VERSION ""

NS_ :

BS_:

BU_: BMS

BO_ 1568 Bat12V: 8 BMS
 SG_ Bat12V_voltage : 15|8@0+ (0.1,0) [0|1] ""  BMS

BO_ 2028 UDS_response: 8 BMS
 SG_ Frame_type M : 7|4@0+ (1,0) [0|1] ""  BMS
 SG_ bytes : 3|4@0+ (1,0) [0|1] ""  BMS
 SG_ Service_ID m0 : 15|8@0+ (1,0) [0|1] ""  BMS
 SG_ Data4 : 39|8@0+ (1,0) [0|1] ""  BMS
 SG_ Data5 : 47|8@0+ (1,0) [0|1] ""  BMS
 SG_ Data6 : 55|8@0+ (1,0) [0|1] ""  BMS
 SG_ Data7 : 63|8@0+ (1,0) [0|1] ""  BMS
 SG_ ReadDataByIdentifie m34 : 23|8@0+ (1,0) [0|1] ""  BMS

BO_ 2147484963 BCM: 8 BMS
 SG_ Ign : 7|4@0+ (1,0) [0|1] ""  BMS
 SG_ AliveCounter : 56|2@1+ (1,0) [0|3] ""  BMS

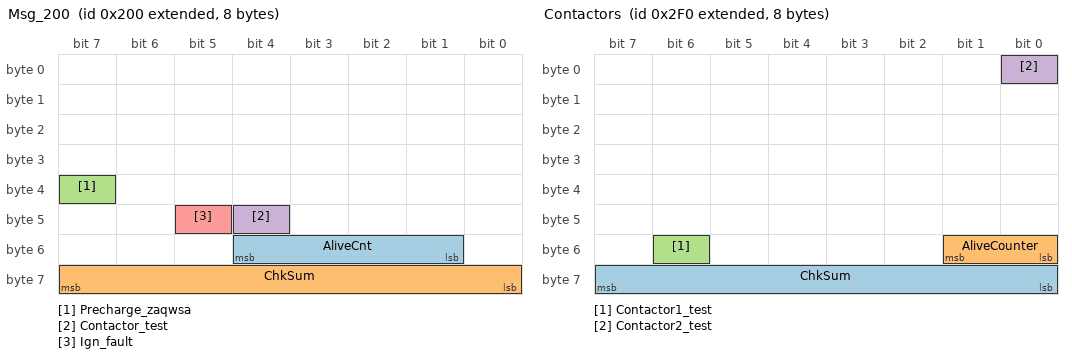
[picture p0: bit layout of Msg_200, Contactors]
BO_ 2147484160 Msg_200: 8 BMS
 SG_ AliveCnt : 49|4@1+ (1,0) [0|1] ""  BMS
 SG_ ChkSum : 56|8@1+ (1,0) [0|1] ""  BMS
 SG_ Precharge_zaqwsa : 39|1@1+ (1,0) [0|1] ""  BMS
 SG_ Contactor_test : 44|1@0+ (1,0) [0|1] ""  BMS
 SG_ Ign_fault : 45|1@0+ (1,0) [0|1] "" Vector__XXX

BO_ 2147484322 Msg_2A2: 8 BMS

BO_ 2147484322 Msg_2A2: 8 BMS

BO_ 2147484161 Msg_201: 8 BMS
 SG_ ChkSum : 56|8@1+ (1,0) [0|1] ""  BMS

BO_ 2147484162 Msg_202: 8 BMS
 SG_ ChkSum : 56|8@1+ (1,0) [0|1] ""  BMS

BO_ 2147484163 Msg_203: 8 BMS
 SG_ ChkSum : 56|8@1+ (1,0) [0|1] ""  BMS
 SG_ AliveCounter : 30|2@1+ (1,0) [0|1] ""  BMS

BO_ 2147484320 Msg_2A0: 8 BMS

BO_ 2147484321 Msg_2A1: 8 BMS
 SG_ Inverter_voltage_bms : 48|8@1+ (1.66,0) [0|1] "V" Vector__XXX

BO_ 2147484336 Msg_2B0: 8 BMS

BO_ 2147484341 Msg_2B5: 8 BMS

BO_ 2147484401 Msg_2F1: 8 BMS

BO_ 2147484964 Msg_524: 8 BMS

BO_ 2147484400 Contactors: 8 BMS
 SG_ ChkSum : 56|8@1+ (1,0) [0|1] ""  BMS
 SG_ AliveCounter : 48|2@1+ (1,0) [0|3] ""  BMS
 SG_ Contactor1_test : 54|1@0+ (1,0) [0|1] ""  BMS
 SG_ Contactor2_test : 0|1@0+ (1,0) [0|1] ""  BMS
